# AT32A423xx_v2 register map
Vendor: Keil; Series: AT32A423; File version: 1.0
CPU: CM4 r0p1, little endian, no MPU, FPU, 4 interrupt priority bits
Registers are 32-bit, read-write, reset 0x0 unless marked. A register's access mark holds for its fields unless they carry their own. Offsets are from the block's base; [hi:lo] are bit positions; lines under a group give offsets from that group; {n}, {i} and the like mark numbered series.

## ADC1 — Analog to digital converter
Base 0x40012000
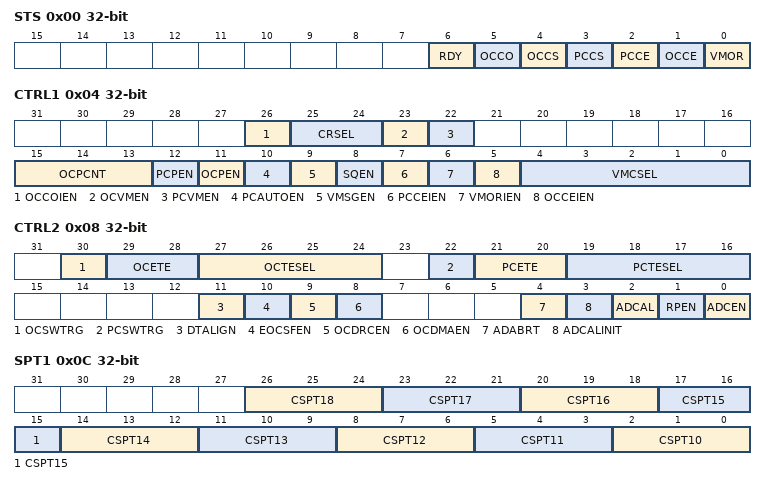
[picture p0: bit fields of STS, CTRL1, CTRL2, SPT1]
0x00 STS — status register
  [6] RDY ro — ADC ready to conversion flag
  [5] OCCO — Ordinary channel conversion overflow flag
  [4] OCCS — Ordinary channel conversion start flag
  [3] PCCS — Preempted channel conversion start flag
  [2] PCCE — Preempted channels conversion end flag
  [1] OCCE — Ordinary channels conversion end flag
  [0] VMOR — Voltage monitoring out of range flag
0x04 CTRL1 — control register 1
  [26] OCCOIEN — Ordinary channel conversion overflow interrupt enable
  [25:24] CRSEL — Conversion resolution select
  [23] OCVMEN — Voltage monitoring enable on ordinary channels
  [22] PCVMEN — Voltage monitoring enable on preempted channels
  [15:13] OCPCNT — Partitioned mode conversion count of ordinary channels
  [12] PCPEN — Partitioned mode enable on preempted channels
  [11] OCPEN — Partitioned mode enable on ordinary channels
  [10] PCAUTOEN — Preempted group automatic conversion enable after ordinary group
  [9] VMSGEN — Voltage monitoring enable on a single channel
  [8] SQEN — Sequence mode enable
  [7] PCCEIEN — Conversion end interrupt enable for preempted channels
  [6] VMORIEN — Voltage monitoring out of range interrupt enable
  [5] OCCEIEN — Ordinary channel conversion end interrupt enable
  [4:0] VMCSEL — Voltage monitoring channel select
0x08 CTRL2 — control register 2
  [30] OCSWTRG — Ordinary channel software conversion trigger
  [29:28] OCETE — Ordinary channel external trigger edge select
  [27:24] OCTESEL — trigger event select for ordinary channels conversion
  [22] PCSWTRG — Preempted channel software conversion trigger
  [21:20] PCETE — Preempted channel external trigger edge select
  [19:16] PCTESEL — trigger event select for preempted channels conversion
  [11] DTALIGN — Data alignment
  [10] EOCSFEN — Each ordinary channel conversion set OCCE flag enable
  [9] OCDRCEN — Ordinary channel DMA request continuation enable for independent mode
  [8] OCDMAEN — Ordinary channel DMA transfer enable for independent mode
  [4] ADABRT — ADC conversion abort
  [3] ADCALINIT — Initialize A/D calibration
  [2] ADCAL — A/D Calibration
  [1] RPEN — Repeat mode enable
  [0] ADCEN — A/D converter enable
0x0C SPT1 — sample time register 1
  [3n-28:3n-30] CSPT{n} (n=10..18) — Selection sample time of channel ADC_IN{n}
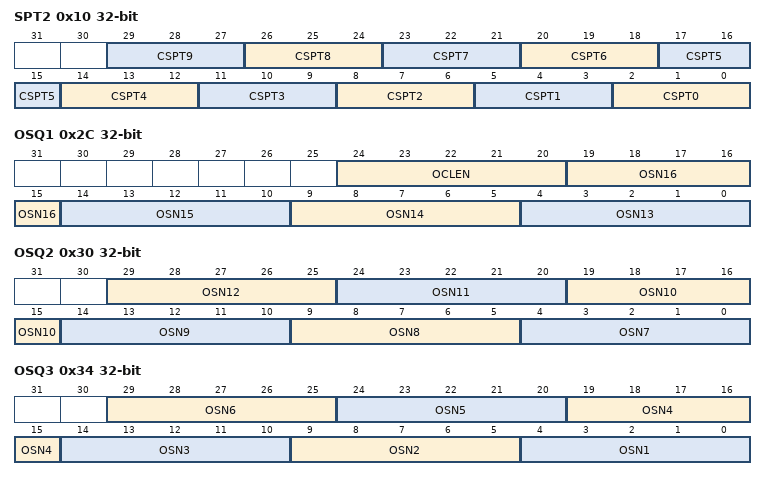
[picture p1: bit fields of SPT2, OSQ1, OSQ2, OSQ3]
0x10 SPT2 — sample time register 2
  [3n+2:3n] CSPT{n} (n=0..9) — Selection sample time of channel ADC_IN{n}
{0x10+4i} PCDTO{i} (i=1..4) — Preempted channel {i} data offset register
  [11:0] PCDTO{i} — Data offset for Preempted channel {i}
0x24 VMHB reset 0xFFF — Voltage monitoring high boundary register
  [15:0] VMHB — Voltage monitoring high boundary
0x28 VMLB — Voltage monitoring low boundary register
  [15:0] VMLB — Voltage monitoring low boundary
0x2C OSQ1 — Ordinary sequence register 1
  [24:20] OCLEN — Ordinary conversion sequence length
  [5n-61:5n-65] OSN{n} (n=13..16) — Number of {n}th conversion in ordinary sequence
0x30 OSQ2 — Ordinary sequence register 2
  [29:25] OSN12 — Number of 12th conversion in ordinary sequence
  [24:20] OSN11 — Number of 11th conversion in ordinary sequence
  [19:15] OSN10 — Number of 10th conversion in ordinary sequence
  [14:10] OSN9 — Number of 8th conversion in ordinary sequence
  [9:5] OSN8 — Number of 7th conversion in ordinary sequence
  [4:0] OSN7 — Number of 13th conversion in ordinary sequence
0x34 OSQ3 — Ordinary sequence register 3
  [29:25] OSN6 — Number of 6th conversion in ordinary sequence
  [24:20] OSN5 — Number of 5th conversion in ordinary sequence
  [19:15] OSN4 — Number of 4th conversion in ordinary sequence
  [14:10] OSN3 — number of 3rd conversion in ordinary sequence
  [9:5] OSN2 — Number of 2nd conversion in ordinary sequence
  [4:0] OSN1 — Number of 1st conversion in ordinary sequence
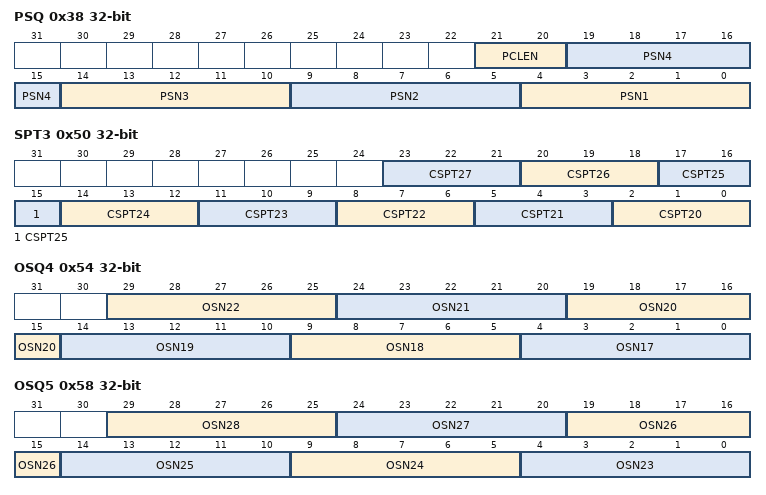
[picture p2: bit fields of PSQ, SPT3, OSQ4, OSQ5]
0x38 PSQ — Preempted sequence register
  [21:20] PCLEN — Preempted conversion sequence length
  [19:15] PSN4 — Number of 4th conversion in Preempted sequence
  [14:10] PSN3 — Number of 3rd conversion in Preempted sequence
  [9:5] PSN2 — Number of 2nd conversion in Preempted sequence
  [4:0] PSN1 — Number of 1st conversion in Preempted sequence
{0x38+4i} PDT{i} ro (i=1..4) — Preempted data register {i}
  [15:0] PDT{i} — Preempted data
0x4C ODT ro — Ordinary data register
  [15:0] ODT — Conversion data of ordinary channel
0x50 SPT3 — sample time register 3
  [3n-58:3n-60] CSPT{n} (n=20..27) — Selection sample time of channel ADC_IN{n}
0x54 OSQ4 — Ordinary sequence register 4
  [29:25] OSN22 — Number of 22th conversion in ordinary sequence
  [24:20] OSN21 — Number of 21th conversion in ordinary sequence
  [19:15] OSN20 — Number of 20th conversion in ordinary sequence
  [14:10] OSN19 — number of 19rd conversion in ordinary sequence
  [9:5] OSN18 — Number of 18nd conversion in ordinary sequence
  [4:0] OSN17 — Number of 17st conversion in ordinary sequence
0x58 OSQ5 — Ordinary sequence register 5
  [29:25] OSN28 — Number of 28th conversion in ordinary sequence
  [24:20] OSN27 — Number of 27th conversion in ordinary sequence
  [19:15] OSN26 — Number of 26th conversion in ordinary sequence
  [14:10] OSN25 — number of 25rd conversion in ordinary sequence
  [9:5] OSN24 — Number of 24nd conversion in ordinary sequence
  [4:0] OSN23 — Number of 23st conversion in ordinary sequence
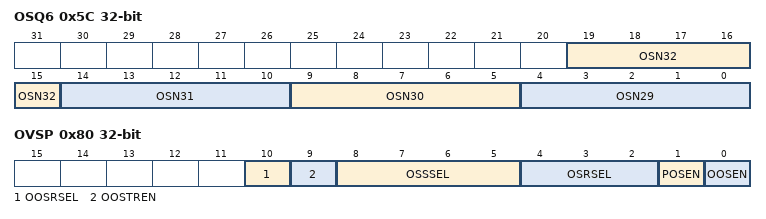
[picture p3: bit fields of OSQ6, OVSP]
0x5C OSQ6 — Ordinary sequence register 6
  [19:15] OSN32 — Number of 32th conversion in ordinary sequence
  [14:10] OSN31 — number of 31rd conversion in ordinary sequence
  [9:5] OSN30 — Number of 30nd conversion in ordinary sequence
  [4:0] OSN29 — Number of 29st conversion in ordinary sequence
0x80 OVSP — oversampling register
  [10] OOSRSEL — Ordinary oversampling recovery mode select
  [9] OOSTREN — Ordinary oversampling trigger mode enable
  [8:5] OSSSEL — Oversampling shift select
  [4:2] OSRSEL — Oversampling ratio select
  [1] POSEN — Preempted oversampling enable
  [0] OOSEN — Ordinary oversampling enable
0xB4 CALVAL — Calibration value register
  [6:0] CALVAL — A/D Calibration value
